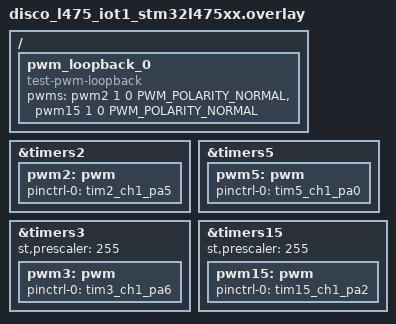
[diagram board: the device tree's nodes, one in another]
/*
 * Copyright (c) 2021 Tilmann Unte
 *
 * SPDX-License-Identifier: Apache-2.0
 */

#include <zephyr/dt-bindings/pwm/pwm.h>

/ {
	pwm_loopback_0 {
		compatible = "test-pwm-loopback";
		/* first index must be a 32-Bit timer */
		pwms = <&pwm2 1 0 PWM_POLARITY_NORMAL>,
			<&pwm15 1 0 PWM_POLARITY_NORMAL>;
	};
};

/* 32-Bit timers */
&timers2 {
	status = "okay";
	pwm2: pwm {
		status = "okay";
		pinctrl-0 = <&tim2_ch1_pa5>; /* CN1 D13 */
		pinctrl-names = "default";
	};
};

&timers5 {
	status = "okay";
	pwm5: pwm {
		status = "okay";
		pinctrl-0 = <&tim5_ch1_pa0>; /* CN3 D1 */
		pinctrl-names = "default";
	};
};

/* 16-Bit timers */
&timers3 {
	status = "okay";
	st,prescaler = <255>;
	pwm3: pwm {
		status = "okay";
		pinctrl-0 = <&tim3_ch1_pa6>; /* CN1 D12 */
		pinctrl-names = "default";
	};
};

&timers15 {
	status = "okay";
	st,prescaler = <255>;
	pwm15: pwm {
		status = "okay";
		pinctrl-0 = <&tim15_ch1_pa2>; /* CN1 D10 */
		pinctrl-names = "default";
	};
};
